# fcr_reva register map
Registers are read-write, no defined reset value unless marked. A register's access mark holds for its fields unless they carry their own. Offsets are from the block's base; lines under a group give offsets from that group; [hi:lo] are bit positions; {n}, {i} and the like mark numbered series; 'fields as' and 'values as' point back to an identical list; <NAME> marks a mode.

## Memory map
0x40000800 FCR size 0x400 — Function Control Register.

## FCR — Function Control Register.
Base 0x40000800
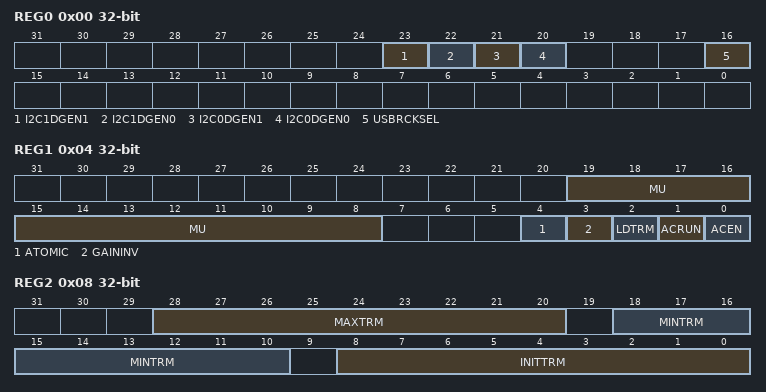
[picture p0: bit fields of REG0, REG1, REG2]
0x00 REG0 — Register 0.
  [23] I2C1DGEN1 — I2C1 SCL Pad Deglitcher enable.
    0=dis (Deglitcher disabled.); 1=en (Deglitcher enabled.)
  [22] I2C1DGEN0 — I2C1 SDA Pad Deglitcher enable.
    0=dis (Deglitcher disabled.); 1=en (Deglitcher enabled.)
  [21] I2C0DGEN1 — I2C0 SCL Pad Deglitcher enable.
    0=dis (Deglitcher disabled.); 1=en (Deglitcher enabled.)
  [20] I2C0DGEN0 — I2C0 SDA Pad Deglitcher enable.
    0=dis (Deglitcher disabled.); 1=en (Deglitcher enabled.)
  [16] USBRCKSEL — USB External Core Clock Select.
    0=sys (Generated clock from system clock.); 1=dig (Digital clock from a GPIO.)
0x04 REG1 — Register 1.
  [19:8] MU — MU value.
  [4] ATOMIC — Atomic mode.
    0=not (Not Running.); 1=run (Running.)
  [3] GAININV — Invert Gain.
    0=not (Not Running.); 1=run (Running.)
  [2] LDTRM — Load Trim.
  [1] ACRUN — Autocalibration Run.
    0=not (Not Running.); 1=run (Running.)
  [0] ACEN — Auto-calibration Enable.
    0=dis (Disabled.); 1=en (Enabled.)
0x08 REG2 — Register 2.
  [28:20] MAXTRM — Maximum Trim Setting.
  [18:10] MINTRM — Minimum Trim Setting.
  [8:0] INITTRM — Initial Trim Setting.
0x0C REG3 — Register 3.
  [7:0] DONECNT — Auto-callibration Done Counter Setting.
